# R7FA4E2B9 register map
Vendor: Renesas Electronics Corporation; Series: RA4; File version: 1.40.00
CPU: CM33 r0p4, little endian, MPU, FPU, VTOR, 4 interrupt priority bits, 96 interrupts
Registers are 32-bit, read-write, reset 0x0 unless marked. A register's access mark holds for its fields unless they carry their own. Offsets are from the block's base; [hi:lo] are bit positions; 'fields as' and 'values as' point back to an identical list.

## MSTP — Module Stop Control
Base 0x40084000
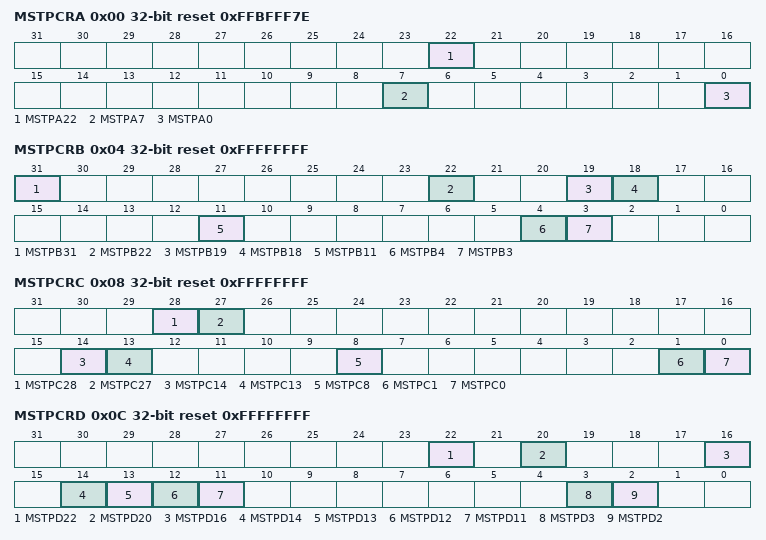
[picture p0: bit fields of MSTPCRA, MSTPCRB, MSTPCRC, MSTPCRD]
0x00 MSTPCRA reset 0xFFBFFF7E — Module Stop Control Register A
  [all] fields
    0=Cancel the module-stop state; 1=Enter the module-stop state
  [22] MSTPA22 — DMA Controller/Data Transfer Controller Module Stop
  [7] MSTPA7 — Standby SRAM Module Stop
  [0] MSTPA0 — SRAM0 Module Stop
0x04 MSTPCRB reset 0xFFFFFFFF — Module Stop Control Register B
  [all] fields
    values as the fields of MSTPCRA
  [31] MSTPB31 — Serial Communication Interface 0 Module Stop
  [22] MSTPB22 — Serial Communication Interface 9 Module Stop
  [19] MSTPB19 — Serial Peripheral Interface 0 Module Stop
  [18] MSTPB18 — Serial Peripheral Interface 1 Module Stop
  [11] MSTPB11 — Universal Serial Bus 2.0 FS Interface 0 Module Stop
  [4] MSTPB4 — I3C Bus Interface 0 Module Stop
  [3] MSTPB3 — CEC Module Stop
0x08 MSTPCRC reset 0xFFFFFFFF — Module Stop Control Register C
  [all] fields
    values as the fields of MSTPCRA
  [28] MSTPC28 — Random Number Generator Module Stop
  [27] MSTPC27 — CANFD Module Stop
  [14] MSTPC14 — Event Link Controller Module Stop
  [13] MSTPC13 — Data Operation Circuit Module Stop
  [8] MSTPC8 — Serial Sound Interface Enhanced Module Stop
  [1] MSTPC1 — Cyclic Redundancy Check Calculator Module Stop
  [0] MSTPC0 — Clock Frequency Accuracy Measurement Circuit Module Stop
0x0C MSTPCRD reset 0xFFFFFFFF — Module Stop Control Register D
  [all] fields
    values as the fields of MSTPCRA
  [22] MSTPD22 — Temperature Sensor Module Stop
  [20] MSTPD20 — 12-bit D/A Converter Module Stop
  [16] MSTPD16 — 12-bit A/D Converter 0 Module Stop
  [14] MSTPD14 — Port Output Enable for GPT Group A Module Stop
  [13] MSTPD13 — Port Output Enable for GPT Group B Module Stop
  [12] MSTPD12 — Port Output Enable for GPT Group C Module Stop
  [11] MSTPD11 — Port Output Enable for GPT Group D Module Stop
  [3] MSTPD3 — Low Power Asynchronous General Purpose Timer 0 Module Stop
  [2] MSTPD2 — Low Power Asynchronous General Purpose Timer 1 Module Stop
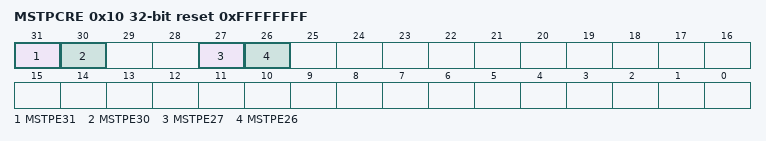
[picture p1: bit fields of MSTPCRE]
0x10 MSTPCRE reset 0xFFFFFFFF — Module Stop Control Register E
  [all] fields
    values as the fields of MSTPCRA
  [31] MSTPE31 — GPT0 Module Stop
  [30] MSTPE30 — GPT1 Module Stop
  [27] MSTPE27 — GPT4 Module Stop
  [26] MSTPE26 — GPT5 Module Stop

## TSN — Temperature Sensor
Base 0x400F3000
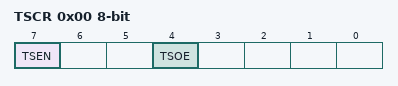
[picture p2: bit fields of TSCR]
0x00 TSCR 8-bit — Temperature Sensor Control Register
  [7] TSEN — Temperature Sensor Enable
    0=Stop the temperature sensor; 1=Start the temperature sensor
  [4] TSOE — Temperature Sensor Output Enable
    0=Disable output from the temperature sensor to the ADC12; 1=Enable output from the temperature sensor to the ADC12

## CRC — Cyclic Redundancy Check Calculator
Base 0x40108000
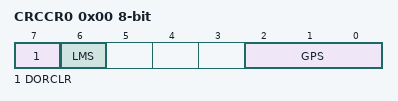
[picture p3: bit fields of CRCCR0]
0x00 CRCCR0 8-bit — CRC Control Register 0
  [7] DORCLR wo — CRCDOR/CRCDOR_HA/CRCDOR_BY Register Clear
    0=No effect; 1=Clear the CRCDOR/CRCDOR_HA/CRCDOR_BY register
  [6] LMS — CRC Calculation Switching
    0=Generate CRC code for LSB-first communication; 1=Generate CRC code for MSB-first communication
  [2:0] GPS — CRC Generating Polynomial Switching
    1=8-bit CRC-8 (X8 + X2 + X + 1); 2=16-bit CRC-16 (X16 + X15 + X2 + 1); 3=16-bit CRC-CCITT (X16 + X12 + X5 + 1); 4=32-bit CRC-32 (X32 + X26 + X23 + X22 + X16 + X12 + X11 +X10 + X8 + X7 + X5 + X4 + X2 + X + 1); 5=32-bit CRC-32C (X32 + X28 + X27 + X26 + X25 + X23 + X22 + X20 + X19 + X18 + X14 + X13 + X11 + X10 + X9 + X8 + X6 + 1); other=Others (No calculation is executed)
0x04 CRCDIR — CRC Data Input Register
0x04 CRCDIR_BY 8-bit (alternate view of CRCDIR) — CRC Data Input Register
0x08 CRCDOR — CRC Data Output Register
0x08 CRCDOR_HA 16-bit (alternate view of CRCDOR) — CRC Data Output Register
0x08 CRCDOR_BY 8-bit (alternate view of CRCDOR) — CRC Data Output Register
